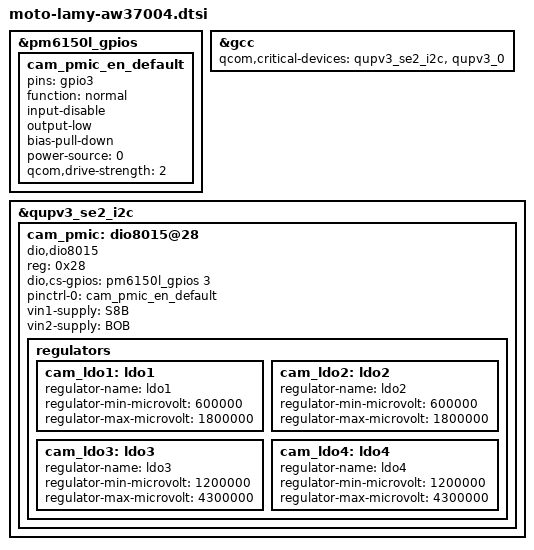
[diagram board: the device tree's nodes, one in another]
/*
 * Each QUP device that's a parent to PMIC must be listed as a critical device
 * to GCC.
 */
&pm6150l_gpios{
	cam_pmic_en_default: cam_pmic_en_default {
		pins = "gpio3";
		function = "normal";
		input-disable;
		output-low;
		bias-pull-down;
		power-source = <0>;
		qcom,drive-strength = <2>;
 	};
};

/*
 * Each QUP device that's a parent to PMIC must be listed as a critical device
 * to GCC.
 */
&gcc {
	qcom,critical-devices = <&qupv3_se2_i2c>, <&qupv3_0>;
};

&qupv3_se2_i2c {
	status = "ok";
	//aw37004 and dio8015 use same driver code
	cam_pmic: dio8015@28 {
		compatible = "dio,dio8015";
		reg = <0x28>;

		dio,cs-gpios = <&pm6150l_gpios 3 0>;
		pinctrl-names = "default";
		pinctrl-0 = <&cam_pmic_en_default>;

		vin1-supply = <&S8B>;
		vin2-supply = <&BOB>;

		regulators {
			cam_ldo1: ldo1 {
				regulator-name = "ldo1";
				regulator-min-microvolt = <600000>;
				regulator-max-microvolt = <1800000>;
			};

			cam_ldo2: ldo2 {
				regulator-name = "ldo2";
				regulator-min-microvolt = <600000>;
				regulator-max-microvolt = <1800000>;
			};

			cam_ldo3: ldo3 {
				regulator-name = "ldo3";
				regulator-min-microvolt = <1200000>;
				regulator-max-microvolt = <4300000>;
			};

			cam_ldo4: ldo4 {
				regulator-name = "ldo4";
				regulator-min-microvolt = <1200000>;
				regulator-max-microvolt = <4300000>;
			};
		};
	};
};
